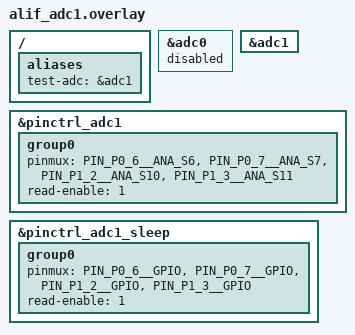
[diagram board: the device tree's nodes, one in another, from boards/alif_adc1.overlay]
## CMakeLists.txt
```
cmake_minimum_required(VERSION 3.20.0)
find_package(Zephyr REQUIRED HINTS $ENV{ZEPHYR_BASE})
project(adc)

target_sources(app PRIVATE
  src/test_adc.c
  src/temperature.c
)

if(CONFIG_TEST_ADC24)
  target_sources(app PRIVATE src/test_adc24.c)
else()
  target_sources(app PRIVATE src/test_adc12.c)
endif()

if(CONFIG_TEST_ADC_DAC)
  target_sources(app PRIVATE src/test_adc_dac.c)
endif()

if(CONFIG_TEST_ADC_THRESHOLD)
  target_sources(app PRIVATE src/test_adc_threshold.c)
endif()

if(CONFIG_TEST_ADC_PGA)
  target_sources(app PRIVATE src/test_adc_pga.c)
endif()
```

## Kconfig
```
config TEST_ADC_DIFFERENTIAL
	bool "To Test ADC in differential mode"

config TEST_ADC_CONTINUOUS
	bool "To Test ADC in continuous mode"

config TEST_ADC_MULTICH
	bool "To Test ADC in multi Channel mode"
	select TEST_ADC_CONTINUOUS
	depends on !TEST_ADC_DIFFERENTIAL || TEST_ADC24
	help
	  Alif ADC does not support multi-channel scan in single-shot mode.
	  Enabling this option also enables continuous conversion. Include
	  the continuous overlay together with the multich overlay, or use
	  a multich overlay that sets CONTINUOUS_CONVERSION.
	  Differential multi-channel is valid with ADC24 only. ADC12 has no
	  test for that combination, so it cannot be selected.

config TEST_ADC24
	bool "To Enable ADC24 testcases"

config TEST_ADC_DAC
	bool "ADC reads DAC0 loopback test"
	depends on !TEST_ADC_MULTICH && (TEST_ADC24 || !TEST_ADC_DIFFERENTIAL)
	select DAC
	help
	  Enable with -DCONFIG_TEST_ADC_DAC=y. Requires an ADC+DAC overlay
	  (alif_adc1_dac0.overlay preferred on B1, or alif_adc12_dac0 /
	  alif_adc24_dac0) so DT alias dac is present. Wire DAC0 P2_3 to
	  the ADC pin described in test_adc_dac.c / README.

config TEST_ADC_THRESHOLD
	bool "ADC comparator threshold and window test"
	help
	  Enable with -DCONFIG_TEST_ADC_THRESHOLD=y. Append a
	  thresh_above, thresh_below, or thresh_window overlay to the
	  matching base ADC overlay.

config TEST_ADC_PGA
	bool "ADC PGA gain test"
	help
	  Enable with -DCONFIG_TEST_ADC_PGA=y. Append a gain overlay
	  (alif_adc1_gain0.overlay, gain12, gain24, gain36, or gain42).
	  Do not combine with CONFIG_TEST_ADC_DAC or CONFIG_TEST_ADC_THRESHOLD.
	  Optionally pass -DCONFIG_TEST_ADC_CHn=y to pick the channel
	  (default channel 1).

config TEST_ADC_CH0
	bool "To enable ADC channel 0 testcase"
	help
	  Enable with -DCONFIG_TEST_ADC_CH0=y on the west build command.

config TEST_ADC_CH1
	bool "To enable ADC channel 1 testcase"
	help
	  Enable with -DCONFIG_TEST_ADC_CH1=y on the west build command.

config TEST_ADC_CH2
	bool "To enable ADC channel 2 testcase"
	help
	  Enable with -DCONFIG_TEST_ADC_CH2=y on the west build command.

config TEST_ADC_CH3
	bool "To enable ADC channel 3 testcase"
	help
	  Enable with -DCONFIG_TEST_ADC_CH3=y on the west build command.

config TEST_ADC_CH4
	bool "To enable ADC channel 4 testcase"
	help
	  Enable with -DCONFIG_TEST_ADC_CH4=y on the west build command.

config TEST_ADC_CH5
	bool "To enable ADC channel 5 testcase"
	help
	  Enable with -DCONFIG_TEST_ADC_CH5=y on the west build command.

config TEST_ADC_CH6
	bool "To enable ADC channel 6 (temperature) testcase"
	help
	  Enable with -DCONFIG_TEST_ADC_CH6=y on the west build command.

config TEST_ADC_CH7
	bool "To enable ADC channel 7 testcase"
	help
	  Enable with -DCONFIG_TEST_ADC_CH7=y on the west build command.

source "Kconfig.zephyr"
```

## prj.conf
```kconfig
CONFIG_ZTEST=y
CONFIG_ADC=y
CONFIG_LOG=y
CONFIG_CBPRINTF_FP_SUPPORT=y
CONFIG_USE_ALIF_HAL_ANALOG=y
CONFIG_ADC_LOG_LEVEL_INF=n
```

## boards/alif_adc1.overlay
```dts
/ {
	aliases {
		test-adc = &adc1;
	};
};

&adc0 {
	status = "disabled";
};

&adc1 {
	status = "okay";
};

/*
 * ADC1 channels 2 and 3 are P1_0 and P1_1, which are also UART2 RX/TX
 * (the RTSS-HE console). Leave those pins as UART so the boot banner
 * and ztest log stay visible. Channels 0, 1, 4, and 5 are unchanged.
 */
&pinctrl_adc1 {
	group0 {
		pinmux = <PIN_P0_6__ANA_S6>,
			 <PIN_P0_7__ANA_S7>,
			 <PIN_P1_2__ANA_S10>,
			 <PIN_P1_3__ANA_S11>;
		read-enable = <1>;
	};
};

&pinctrl_adc1_sleep {
	group0 {
		pinmux = <PIN_P0_6__GPIO>,
			 <PIN_P0_7__GPIO>,
			 <PIN_P1_2__GPIO>,
			 <PIN_P1_3__GPIO>;
		read-enable = <1>;
	};
};
```

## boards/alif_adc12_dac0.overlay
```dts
/ {
	aliases {
		test-adc = &adc0;
		dac = &dac0;
	};
};

&adc0 {
	status = "okay";
};

&dac0 {
	status = "okay";
};
```

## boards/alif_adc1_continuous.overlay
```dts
&adc0 {
	status = "disabled";
};

&adc1 {
	adc_conversion_mode	= "CONTINUOUS_CONVERSION";
	status = "okay";
};
```

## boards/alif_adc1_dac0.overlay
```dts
/*
 * ADC12 instance 1 + DAC0 loopback (Balletto / B1 preferred).
 * Wire DAC0 P2_3 to ADC1 channel 0 P0_6.
 * Avoids ADC0 channel 0 P0_0, which shares UART0 RX and often sits near 1.8 V.
 */
/ {
	aliases {
		test-adc = &adc1;
		dac = &dac0;
	};
};

&adc0 {
	status = "disabled";
};

&adc1 {
	status = "okay";
};

&dac0 {
	status = "okay";
};
```

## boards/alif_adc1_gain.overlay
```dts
&adc1 {
		pga_enable;
		pga_gain = "ADC_PGA_GAIN_42_DB";
};
```

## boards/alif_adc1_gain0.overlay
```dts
&adc1 {
		pga_enable;
		pga_gain = "ADC_PGA_GAIN_0_DB";
};
```

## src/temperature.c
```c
/* Copyright (C) Alif Semiconductor - All Rights Reserved.
 * Use, distribution and modification of this code is permitted under the
 * terms stated in the Alif Semiconductor Software License Agreement
 *
 * You should have received a copy of the Alif Semiconductor Software
 * License Agreement with this file. If not, please write to:
 * contact@alifsemi.com, or visit: https://alifsemi.com/license
 */

#include "temperature.h"

const float tempData[][2] = {
	{918, -40.0},
	{919, -39.6},
	{920, -39.2},
	{921, -38.8},
	{922, -38.4},
	{923, -38.0},
	{924, -37.6},
	{925, -37.2},
	{926, -36.8},
	{927, -36.4},
	{928, -36.0},
	{929, -35.6},
	{930, -35.2},
	{931, -34.8},
	{932, -34.4},
	{933, -34.0},
	{934, -33.6},
	{935, -33.2},
	{936, -32.8},
	{937, -32.4},
	{938, -32.0},
	{939, -31.6},
	{940, -31.2},
	{941, -30.8},
	{942, -30.4},
	{943, -30.0},
	{944, -29.8},
	{945, -29.7},
	{946, -29.5},
	{947, -29.3},
	{948, -29.2},
	{949, -29.0},
	{950, -28.8},
	{951, -28.7},
	{952, -28.5},
	{953, -28.3},
	{954, -28.2},
	{955, -28.0},
	{956, -27.8},
	{957, -27.7},
	{958, -27.5},
	{959, -27.3},
	{960, -27.2},
	{961, -27.0},
	{962, -26.8},
	{963, -26.7},
	{964, -26.5},
	{965, -26.3},
	{966, -26.2},
	{967, -26.0},
	{968, -25.8},
	{969, -25.7},
	{970, -25.5},
	{971, -25.3},
	{972, -25.2},
	{973, -25.0},
	{974, -24.8},
	{975, -24.7},
	{976, -24.5},
	{977, -24.3},
	{978, -24.2},
	{979, -24.0},
	{980, -23.8},
	{981, -23.7},
	{982, -23.5},
	{983, -23.3},
	{984, -23.2},
	{985, -23.0},
	{986, -22.8},
	{987, -22.7},
	{988, -22.5},
	{989, -22.3},
	{990, -22.2},
	{991, -22.0},
	{992, -21.8},
	{993, -21.7},
	{994, -21.5},
	{995, -21.3},
	{996, -21.2},
	{997, -21.0},
	{998, -20.8},
	{999, -20.7},
	{1000, -20.5},
	{1001, -20.3},
	{1002, -20.2},
	{1003, -20.0},
	{1004, -19.2},
	{1005, -18.5},
	{1006, -17.7},
	{1007, -16.9},
	{1008, -16.2},
	{1009, -15.4},
	{1010, -14.6},
	{1011, -13.8},
	{1012, -13.1},
	{1013, -12.3},
	{1014, -11.5},
	{1015, -10.8},
	{1016, -10.0},
	{1017, -9.4},
	{1018, -8.8},
	{1019, -8.1},
	{1020, -7.5},
	{1021, -6.9},
	{1022, -6.3},
	{1023, -5.6},
	{1024, -5.0},
	{1025, -4.4},
	{1026, -3.8},
	{1027, -3.1},
	{1028, -2.5},
	{1029, -1.9},
	{1030, -1.3},
	{1031, -0.6},
	{1032, 0.0},
	{1033, 0.7},
	{1034, 1.3},
	{1035, 2.0},
	{1036, 2.7},
	{1037, 3.3},
	{1038, 4.0},
	{1039, 4.7},
	{1040, 5.3},
	{1041, 6.0},
	{1042, 6.7},
	{1043, 7.3},
	{1044, 8.0},
	{1045, 8.7},
	{1046, 9.3},
	{1047, 10.0},
	{1048, 10.4},
	{1049, 10.9},
	{1050, 11.3},
	{1051, 11.7},
	{1052, 12.2},
	{1053, 12.6},
	{1054, 13.0},
	{1055, 13.5},
	{1056, 13.9},
	{1057, 14.3},
	{1058, 14.8},
	{1059, 15.2},
	{1060, 15.7},
	{1061, 16.1},
	{1062, 16.5},
	{1063, 17.0},
	{1064, 17.4},
	{1065, 17.8},
	{1066, 18.3},
	{1067, 18.7},
	{1068, 19.1},
	{1069, 19.6},
	{1070, 20.0},
	{1071, 20.2},
	{1072, 20.3},
	{1073, 20.5},
	{1074, 20.7},
	{1075, 20.9},
	{1076, 21.0},
	{1077, 21.2},
	{1078, 21.4},
	{1079, 21.6},
	{1080, 21.7},
	{1081, 21.9},
	{1082, 22.1},
	{1083, 22.2},
	{1084, 22.4},
	{1085, 22.6},
	{1086, 22.8},
	{1087, 22.9},
	{1088, 23.1},
	{1089, 23.3},
	{1090, 23.4},
	{1091, 23.6},
	{1092, 23.8},
	{1093, 24.0},
	{1094, 24.1},
	{1095, 24.3},
	{1096, 24.5},
	{1097, 24.7},
	{1098, 24.8},
	{1099, 25.0},
	{1100, 25.2},
	{1101, 25.3},
	{1102, 25.5},
	{1103, 25.7},
	{1104, 25.9},
	{1105, 26.0},
	{1106, 26.2},
	{1107, 26.4},
	{1108, 26.6},
	{1109, 26.7},
	{1110, 26.9},
	{1111, 27.1},
	{1112, 27.2},
	{1113, 27.4},
	{1114, 27.6},
	{1115, 27.8},
	{1116, 27.9},
	{1117, 28.1},
	{1118, 28.3},
	{1119, 28.4},
	{1120, 28.6},
	{1121, 28.8},
	{1122, 29.0},
	{1123, 29.1},
	{1124, 29.3},
	{1125, 29.5},
	{1126, 29.7},
	{1127, 29.8},
	{1128, 30.0},
	{1129, 30.3},
	{1130, 30.5},
	{1131, 30.8},
	{1132, 31.0},
	{1133, 31.3},
	{1134, 31.5},
	{1135, 31.8},
	{1136, 32.0},
	{1137, 32.3},
	{1138, 32.5},
	{1139, 32.8},
	{1140, 33.0},
	{1141, 33.3},
	{1142, 33.5},
	{1143, 33.8},
	{1144, 34.0},
	{1145, 34.3},
	{1146, 34.5},
	{1147, 34.8},
	{1148, 35.0},
	{1149, 35.3},
	{1150, 35.5},
	{1151, 35.8},
	{1152, 36.0},
	{1153, 36.3},
	{1154, 36.5},
	{1155, 36.8},
	{1156, 37.0},
	{1157, 37.3},
	{1158, 37.5},
	{1159, 37.8},
	{1160, 38.0},
	{1161, 38.3},
	{1162, 38.5},
	{1163, 38.8},
	{1164, 39.0},
	{1165, 39.3},
	{1166, 39.5},
	{1167, 39.8},
	{1168, 40.0},
	{1169, 40.5},
	{1170, 40.9},
	{1171, 41.4},
	{1172, 41.8},
	{1173, 42.3},
	{1174, 42.7},
	{1175, 43.2},
	{1176, 43.6},
	{1177, 44.1},
	{1178, 44.5},
	{1179, 45.0},
	{1180, 45.5},
	{1181, 45.9},
	{1182, 46.4},
	{1183, 46.8},
	{1184, 47.3},
	{1185, 47.7},
	{1186, 48.2},
	{1187, 48.6},
	{1188, 49.1},
	{1189, 49.5},
	{1190, 50.0},
	{1191, 50.2},
	{1192, 50.3},
	{1193, 50.5},
	{1194, 50.7},
	{1195, 50.9},
	{1196, 51.0},
	{1197, 51.2},
	{1198, 51.4},
	{1199, 51.6},
	{1200, 51.7},
	{1201, 51.9},
	{1202, 52.1},
	{1203, 52.2},
	{1204, 52.4},
	{1205, 52.6},
	{1206, 52.8},
	{1207, 52.9},
	{1208, 53.1},
	{1209, 53.3},
	{1210, 53.4},
	{1211, 53.6},
	{1212, 53.8},
	{1213, 54.0},
	{1214, 54.1},
	{1215, 54.3},
	{1216, 54.5},
	{1217, 54.7},
	{1218, 54.8},
	{1219, 55.0},
	{1220, 55.2},
	{1221, 55.3},
	{1222, 55.5},
	{1223, 55.7},
	{1224, 55.9},
	{1225, 56.0},
	{1226, 56.2},
	{1227, 56.4},
	{1228, 56.6},
	{1229, 56.7},
	{1230, 56.9},
	{1231, 57.1},
	{1232, 57.2},
	{1233, 57.4},
	{1234, 57.6},
	{1235, 57.8},
	{1236, 57.9},
	{1237, 58.1},
	{1238, 58.3},
	{1239, 58.4},
	{1240, 58.6},
	{1241, 58.8},
	{1242, 59.0},
	{1243, 59.1},
	{1244, 59.3},
	{1245, 59.5},
	{1246, 59.7},
	{1247, 59.8},
	{1248, 60.0},
	{1249, 60.3},
	{1250, 60.7},
	{1251, 61.0},
	{1252, 61.3},
	{1253, 61.7},
	{1254, 62.0},
	{1255, 62.3},
	{1256, 62.7},
	{1257, 63.0},
	{1258, 63.3},
	{1259, 63.7},
	{1260, 64.0},
	{1261, 64.3},
	{1262, 64.7},
	{1263, 65.0},
	{1264, 65.3},
	{1265, 65.7},
	{1266, 66.0},
	{1267, 66.3},
	{1268, 66.7},
	{1269, 67.0},
	{1270, 67.3},
	{1271, 67.7},
	{1272, 68.0},
	{1273, 68.3},
	{1274, 68.7},
	{1275, 69.0},
	{1276, 69.3},
	{1277, 69.7},
	{1278, 70.0},
	{1279, 70.4},
	{1280, 70.9},
	{1281, 71.3},
	{1282, 71.7},
	{1283, 72.2},
	{1284, 72.6},
	{1285, 73.0},
	{1286, 73.5},
	{1287, 73.9},
	{1288, 74.3},
	{1289, 74.8},
	{1290, 75.2},
	{1291, 75.7},
	{1292, 76.1},
	{1293, 76.5},
	{1294, 77.0},
	{1295, 77.4},
	{1296, 77.8},
	{1297, 78.3},
	{1298, 78.7},
	{1299, 79.1},
	{1300, 79.6},
	{1301, 80.0},
	{1302, 80.5},
	{1303, 81.1},
	{1304, 81.6},
	{1305, 82.1},
	{1306, 82.6},
	{1307, 83.2},
	{1308, 83.7},
	{1309, 84.2},
	{1310, 84.7},
	{1311, 85.3},
	{1312, 85.8},
	{1313, 86.3},
	{1314, 86.8},
	{1315, 87.4},
	{1316, 87.9},
	{1317, 88.4},
	{1318, 88.9},
	{1319, 89.5},
	{1320, 90.0}
};

float get_temperature(uint32_t adc_value)
{
	uint32_t i;

	/* check for temperature operating range */
	if (adc_value < tempData[0][0] || (adc_value > tempData[MAX_TEMP_RANGE][0])) {
		return -1;
	}

	for (i = 0; i < ARRAY_SIZE(tempData) ; i++) {
		/* check if value matches with tempdata */
		if (adc_value == tempData[i][0]) {
			return tempData[i][1];
		}
	}

	/* no entry for this value */
	return -1;
}
```

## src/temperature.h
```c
/* Copyright (C) Alif Semiconductor - All Rights Reserved.
 * Use, distribution and modification of this code is permitted under the
 * terms stated in the Alif Semiconductor Software License Agreement
 *
 * You should have received a copy of the Alif Semiconductor Software
 * License Agreement with this file. If not, please write to:
 * contact@alifsemi.com, or visit: https://alifsemi.com/license
 */

#ifndef TEMPERATURE_H_
#define TEMPERATURE_H_

#include <stdint.h>

#include <zephyr/sys/util.h>

#define MAX_TEMP_RANGE 402

/* Declaration of the 2D array and function */
extern const float tempData[][2];
float get_temperature(uint32_t adc_value);

#endif /* TEMPERATURE_H_ */
```

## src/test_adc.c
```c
/* Copyright (C) Alif Semiconductor - All Rights Reserved.
 * Use, distribution and modification of this code is permitted under the
 * terms stated in the Alif Semiconductor Software License Agreement
 *
 * You should have received a copy of the Alif Semiconductor Software
 * License Agreement with this file. If not, please write to:
 * contact@alifsemi.com, or visit: https://alifsemi.com/license
 */

#include <string.h>

#include "test_adc.h"

LOG_MODULE_REGISTER(ALIF_ADC, LOG_LEVEL_INF);

uint32_t buffer[8];
uint32_t All_channel;
uint32_t m_samplings_done;
uint8_t comparator;
uint32_t comp_value[MAX_NUM_THRESHOLD];

enum adc_action adc_call_back(const struct device *dev,
			      const struct adc_sequence *sequence,
			      uint16_t sampling_index)
{
	ARG_UNUSED(dev);
	ARG_UNUSED(sequence);

	LOG_INF("sampling index 0x%X", sampling_index);

	if (comparator & ADC_COMPARATOR_THRESHOLD_ABOVE_A) {
		comp_value[0] += 1;
	}
	if (comparator & ADC_COMPARATOR_THRESHOLD_ABOVE_B) {
		comp_value[1] += 1;
	}
	if (comparator & ADC_COMPARATOR_THRESHOLD_BELOW_A) {
		comp_value[2] += 1;
	}
	if (comparator & ADC_COMPARATOR_THRESHOLD_BELOW_B) {
		comp_value[3] += 1;
	}
	if (comparator & ADC_COMPARATOR_THRESHOLD_BETWEEN_A_B) {
		comp_value[4] += 1;
	}
	if (comparator & ADC_COMPARATOR_THRESHOLD_OUTSIDE_A_B) {
		comp_value[5] += 1;
	}

	++m_samplings_done;

	if (m_samplings_done < 2) {
		return ADC_ACTION_REPEAT;
	}

	return ADC_ACTION_FINISH;
}

void adc_test_reset(void)
{
	uint32_t i;

	m_samplings_done = 0;
	comparator = 0;
	memset(comp_value, 0, sizeof(comp_value));
	for (i = 0; i < ARRAY_SIZE(buffer); i++) {
		buffer[i] = ADC_SAMPLE_SENTINEL;
	}
}

void adc_assert_samples(uint32_t channels)
{
	uint32_t count = POPCOUNT(channels);
	uint32_t i;

	zassert_equal(m_samplings_done, 2,
		      "sampling callback count %u, expected 2",
		      m_samplings_done);
	zassert_true(count > 0 && count <= ARRAY_SIZE(buffer),
		     "channel mask 0x%x does not fit the sample buffer",
		     channels);

	for (i = 0; i < count; i++) {
		zassert_not_equal(buffer[i], ADC_SAMPLE_SENTINEL,
				  "requested channel sample %u was not written", i);
	}
}

static void adc_before(void *fixture)
{
	ARG_UNUSED(fixture);
	adc_test_reset();
}

#if CONFIG_TEST_ADC_MULTICH
#if !DT_NODE_HAS_PROP(DT_ALIAS(test_adc), adc_channel_scan)
#error "MULTICH needs adc_channel_scan (use alif_adc1/24_multich.overlay)"
#elif !DT_ENUM_HAS_VALUE(DT_ALIAS(test_adc), adc_channel_scan, MULTIPLE_CHANNEL_SCAN)
#error "adc_channel_scan must be MULTIPLE_CHANNEL_SCAN"
#endif
#if !DT_NODE_HAS_PROP(DT_ALIAS(test_adc), adc_conversion_mode)
#error "MULTICH needs CONTINUOUS_CONVERSION (single-shot + scan unsupported)"
#elif !DT_ENUM_HAS_VALUE(DT_ALIAS(test_adc), adc_conversion_mode, CONTINUOUS_CONVERSION)
#error "MULTICH needs CONTINUOUS_CONVERSION (single-shot + scan unsupported)"
#endif
#endif

#if CONFIG_TEST_ADC_CONTINUOUS
#if !DT_NODE_HAS_PROP(DT_ALIAS(test_adc), adc_conversion_mode)
#error "CONTINUOUS needs adc_conversion_mode (use continuous overlay)"
#elif !DT_ENUM_HAS_VALUE(DT_ALIAS(test_adc), adc_conversion_mode, CONTINUOUS_CONVERSION)
#error "adc_conversion_mode must be CONTINUOUS_CONVERSION"
#endif
#endif

#if CONFIG_TEST_ADC_THRESHOLD
#include <zephyr/dt-bindings/adc/adc_alif.h>
#if !DT_NODE_HAS_PROP(DT_ALIAS(test_adc), interrupt_en)
#error "THRESHOLD needs interrupt_en (append a thresh_above/below/window overlay)"
#elif ((DT_PROP(DT_ALIAS(test_adc), interrupt_en) & \
	(ADC_COMPA_INTERRUPT | ADC_COMPB_INTERRUPT)) != \
	(ADC_COMPA_INTERRUPT | ADC_COMPB_INTERRUPT))
#error "THRESHOLD needs COMPA+COMPB; append a thresh_* overlay"
#endif
#endif

#if CONFIG_TEST_ADC_PGA
#if !DT_PROP_OR(DT_ALIAS(test_adc), pga_enable, 0)
#error "PGA needs pga_enable; append a gain overlay (e.g. alif_adc1_gain0.overlay)"
#endif
#endif

#if (CONFIG_TEST_ADC24)
#if (CONFIG_TEST_ADC_MULTICH)
ZTEST_SUITE(adc24_multi_channel, NULL, NULL, adc_before, NULL, NULL);
#else
ZTEST_SUITE(adc24_differential, NULL, NULL, adc_before, NULL, NULL);
#endif
#else
#if (CONFIG_TEST_ADC_MULTICH)
ZTEST_SUITE(adc12_multi_channel, NULL, NULL, adc_before, NULL, NULL);
#elif (CONFIG_TEST_ADC_DIFFERENTIAL)
ZTEST_SUITE(adc12_differential, NULL, NULL, adc_before, NULL, NULL);
#else
ZTEST_SUITE(adc_single_ended, NULL, NULL, adc_before, NULL, NULL);
#endif
#endif
```

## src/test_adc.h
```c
/* Copyright (C) Alif Semiconductor - All Rights Reserved.
 * Use, distribution and modification of this code is permitted under the
 * terms stated in the Alif Semiconductor Software License Agreement
 *
 * You should have received a copy of the Alif Semiconductor Software
 * License Agreement with this file. If not, please write to:
 * contact@alifsemi.com, or visit: https://alifsemi.com/license
 */
#ifndef TEST_ADC_H_
#define TEST_ADC_H_

#include <inttypes.h>
#include <stddef.h>
#include <stdint.h>

#include <zephyr/device.h>
#include <zephyr/devicetree.h>
#include <zephyr/drivers/adc.h>
#include <zephyr/kernel.h>
#include <zephyr/sys/printk.h>
#include <zephyr/sys/util.h>
#include "temperature.h"
#include <zephyr/ztest.h>
#include <zephyr/logging/log.h>


extern uint32_t buffer[8];
extern uint32_t All_channel;
#define ADC_CHANNEL_0				(0x00)
#define ADC_CHANNEL_1				(0x01)
#define ADC_CHANNEL_2				(0x02)
#define ADC_CHANNEL_3				(0x03)
#define ADC_CHANNEL_4				(0x04)
#define ADC_CHANNEL_5				(0x05)
#define ADC_CHANNEL_6				(0x06)
#define ADC_CHANNEL_7				(0x07)
#define ADC_CHANNEL_8				(0x08)

/****ADC MASK CHANNEL****/
#define ADC_UNMASK_CHANNEL_0			(1 << 0)
#define ADC_UNMASK_CHANNEL_1			(1 << 1)
#define ADC_UNMASK_CHANNEL_2			(1 << 2)
#define ADC_UNMASK_CHANNEL_3			(1 << 3)
#define ADC_UNMASK_CHANNEL_4			(1 << 4)
#define ADC_UNMASK_CHANNEL_5			(1 << 5)
#define ADC_UNMASK_CHANNEL_6			(1 << 6)
#define ADC_UNMASK_CHANNEL_7			(1 << 7)
#define ADC_UNMASK_CHANNEL_8			(1 << 8)

#define ADC_COMPARATOR_THRESHOLD_ABOVE_A	(1 << 0)
#define ADC_COMPARATOR_THRESHOLD_ABOVE_B	(1 << 1)
#define ADC_COMPARATOR_THRESHOLD_BELOW_A	(1 << 2)
#define ADC_COMPARATOR_THRESHOLD_BELOW_B	(1 << 3)
#define ADC_COMPARATOR_THRESHOLD_BETWEEN_A_B	(1 << 4)
#define ADC_COMPARATOR_THRESHOLD_OUTSIDE_A_B	(1 << 5)

#define TEMPERATURE_SENSOR			ADC_CHANNEL_6
#define MAX_NUM_THRESHOLD			(6)

extern uint32_t m_samplings_done;
extern uint8_t comparator;

extern uint32_t comp_value[MAX_NUM_THRESHOLD];

/*
 * Not a legal conversion result. Single-ended samples stay within 20 bits.
 * Differential samples are sign-extended, so a negative value has the sign
 * bit and every bit above it set. This value has bit 30 set and bit 31 clear.
 */
#define ADC_SAMPLE_SENTINEL			0x7FFFFFFF

#define ADC	DT_ALIAS(test_adc)

enum adc_action adc_call_back(const struct device *dev,
			      const struct adc_sequence *sequence,
			      uint16_t sampling_index);

void adc_test_reset(void);

void adc_assert_samples(uint32_t channels);

#endif /* TEST_ADC_H_ */
```

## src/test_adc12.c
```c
/* Copyright (C) Alif Semiconductor - All Rights Reserved.
 * Use, distribution and modification of this code is permitted under the
 * terms stated in the Alif Semiconductor Software License Agreement
 *
 * You should have received a copy of the Alif Semiconductor Software
 * License Agreement with this file. If not, please write to:
 * contact@alifsemi.com, or visit: https://alifsemi.com/license
 */

#include "test_adc.h"

#if !CONFIG_TEST_ADC24

LOG_MODULE_DECLARE(ALIF_ADC, LOG_LEVEL_INF);

static int test_channels(int channel, int mask)
{
	float temp;
	int ret;
	uint32_t channels;

	struct adc_sequence_options adc_seq_options = {
		.callback	= adc_call_back,
		.user_data	= (uint8_t *)&comparator,
	};

	const struct device *adc_dev = DEVICE_DT_GET(ADC);

	zassert_true(device_is_ready(adc_dev), "ADC device is not ready");

	struct adc_channel_cfg channel_cfg = {
#if CONFIG_TEST_ADC_DIFFERENTIAL
		.differential = 1,
#else
		.differential = 0,
#endif
		.channel_id   = All_channel ? ADC_CHANNEL_0 : channel,
	};

	if (IS_ENABLED(CONFIG_TEST_ADC_MULTICH)) {
		LOG_INF("ADC12 multi-channel scan (continuous)");
	} else if (All_channel && IS_ENABLED(CONFIG_TEST_ADC_DIFFERENTIAL)) {
		LOG_INF("ADC12 with differential");
	} else if (!IS_ENABLED(CONFIG_TEST_ADC_DIFFERENTIAL) &&
		   IS_ENABLED(CONFIG_TEST_ADC_CONTINUOUS)) {
		LOG_INF("ADC12 single ended continuous");
	} else if (IS_ENABLED(CONFIG_TEST_ADC_DIFFERENTIAL) &&
		   IS_ENABLED(CONFIG_TEST_ADC_CONTINUOUS)) {
		LOG_INF("ADC12 Differential and continuous feature selected");
	} else {
		LOG_INF("ADC12 Single ended");
	}

	if (IS_ENABLED(CONFIG_TEST_ADC_CONTINUOUS) || All_channel) {
#if CONFIG_TEST_ADC_DIFFERENTIAL
		channels = ADC_UNMASK_CHANNEL_0 | ADC_UNMASK_CHANNEL_1 | ADC_UNMASK_CHANNEL_2;
#else
		/* Balletto ADC12 has no channel 7 (Vref). E1C, E7, and E8 keep it. */
		channels = ADC_UNMASK_CHANNEL_0 | ADC_UNMASK_CHANNEL_1 | ADC_UNMASK_CHANNEL_2
			 | ADC_UNMASK_CHANNEL_3 | ADC_UNMASK_CHANNEL_4 | ADC_UNMASK_CHANNEL_5
			 | ADC_UNMASK_CHANNEL_6;
		if (!IS_ENABLED(CONFIG_SOC_FAMILY_BALLETTO)) {
			channels |= ADC_UNMASK_CHANNEL_7;
		}
#endif
	} else {
		channels = mask;
	}

	struct adc_sequence sequence = {
		.options	= &adc_seq_options,
		.buffer		= (void *)buffer,
		.buffer_size	= sizeof(buffer),
		.channels	= channels,
	};

	/* Set the channel */
	ret = adc_channel_setup(adc_dev, &channel_cfg);
	if (!IS_ENABLED(CONFIG_TEST_ADC_CONTINUOUS) &&
	    IS_ENABLED(CONFIG_TEST_ADC_DIFFERENTIAL) &&
	    (channel > ADC_CHANNEL_2)) {
		zassert_equal(ret, -EINVAL,
			      "invalid channel setup passed, ret %d", ret);
		LOG_INF("channel setup failed as expected, ret %d", ret);
		return TC_PASS;
	}
	zassert_equal(ret, 0, "Unable set up channel, code %d", ret);

	/* Start reading the samples */
	ret = adc_read(adc_dev, &sequence);
	zassert_equal(ret, 0, "adc_read() failed with code %d", ret);
	adc_assert_samples(channels);

	LOG_INF("Allocated memory buffer Address is %p", (void *)buffer);

	if (channel_cfg.channel_id == ADC_CHANNEL_6) {
		LOG_INF("Allocated memory buffer Address is %p and value is %x",
			(void *)buffer, buffer[0]);
		temp = (float) get_temperature(buffer[0]);
		if (temp == -1) {
			LOG_ERR(" Error: Temperature is outside range");
			ztest_test_fail();
		} else {
			LOG_INF("Current temp %0.1f C", (double)temp);
		}
	}

#if CONFIG_TEST_ADC_CONTINUOUS
	for (uint32_t i = 0; i < POPCOUNT(channels); i++) {
		LOG_INF("Channel%d value is %x", i, buffer[i]);
	}
#else
	LOG_INF("Channel %d value is %x", channel, buffer[0]);
#endif

	LOG_INF("ADC sampling Done");
	return TC_PASS;
}

#if !(CONFIG_TEST_ADC_DIFFERENTIAL || CONFIG_TEST_ADC_CONTINUOUS || \
	CONFIG_TEST_ADC_MULTICH || CONFIG_TEST_ADC_PGA || CONFIG_TEST_ADC_THRESHOLD)

#if CONFIG_TEST_ADC_CH0
ZTEST(adc_single_ended, test_adc_single_ended_input_channel0)
{
	zassert_true(test_channels(ADC_CHANNEL_0, ADC_UNMASK_CHANNEL_0) == TC_PASS);
}
#endif

#if CONFIG_TEST_ADC_CH1
ZTEST(adc_single_ended, test_adc_single_ended_input_channel1)
{
	zassert_true(test_channels(ADC_CHANNEL_1, ADC_UNMASK_CHANNEL_1) == TC_PASS);
}
#endif

#if CONFIG_TEST_ADC_CH2
ZTEST(adc_single_ended, test_adc_single_ended_input_channel2)
{
	zassert_true(test_channels(ADC_CHANNEL_2, ADC_UNMASK_CHANNEL_2) == TC_PASS);
}
#endif

#if CONFIG_TEST_ADC_CH3
ZTEST(adc_single_ended, test_adc_single_ended_input_channel3)
{
	zassert_true(test_channels(ADC_CHANNEL_3, ADC_UNMASK_CHANNEL_3) == TC_PASS);
}
#endif

#if CONFIG_TEST_ADC_CH4
ZTEST(adc_single_ended, test_adc_single_ended_input_channel4)
{
	zassert_true(test_channels(ADC_CHANNEL_4, ADC_UNMASK_CHANNEL_4) == TC_PASS);
}
#endif

#if CONFIG_TEST_ADC_CH5
ZTEST(adc_single_ended, test_adc_single_ended_input_channel5)
{
	zassert_true(test_channels(ADC_CHANNEL_5, ADC_UNMASK_CHANNEL_5) == TC_PASS);
}
#endif

#if CONFIG_TEST_ADC_CH6
ZTEST(adc_single_ended, test_adc_single_ended_input_channel6)
{
	zassert_true(test_channels(ADC_CHANNEL_6, ADC_UNMASK_CHANNEL_6) == TC_PASS);
}
#endif

#if CONFIG_TEST_ADC_CH7 && !IS_ENABLED(CONFIG_SOC_FAMILY_BALLETTO)
ZTEST(adc_single_ended, test_adc_single_ended_input_channel7)
{
	zassert_true(test_channels(ADC_CHANNEL_7, ADC_UNMASK_CHANNEL_7) == TC_PASS);
}
#endif
#endif

#if (CONFIG_TEST_ADC_CONTINUOUS && !CONFIG_TEST_ADC_DIFFERENTIAL && !CONFIG_TEST_ADC_MULTICH)
ZTEST(adc_single_ended, test_adc_ContinuousMode)
{
	All_channel = 1;
	zassert_true(test_channels(0, 0) == TC_PASS);
	All_channel = 0;
}
#endif

#if (CONFIG_TEST_ADC_MULTICH && !CONFIG_TEST_ADC_DIFFERENTIAL)
ZTEST(adc12_multi_channel, test_adc_continuous_Mode_with_multi_channel)
{
	All_channel = 1;
	zassert_true(test_channels(0, 0) == TC_PASS);
	All_channel = 0;
}
#endif

#if (CONFIG_TEST_ADC_DIFFERENTIAL && !CONFIG_TEST_ADC_CONTINUOUS && !CONFIG_TEST_ADC_MULTICH)

#if (CONFIG_TEST_ADC_CH0 && CONFIG_TEST_ADC_CH1)
ZTEST(adc12_differential, test_adc_channel_0_diff_input)
{
	zassert_true(test_channels(ADC_CHANNEL_0, ADC_UNMASK_CHANNEL_0) == TC_PASS);
}
#endif

#if (CONFIG_TEST_ADC_CH2 && CONFIG_TEST_ADC_CH3)
ZTEST(adc12_differential, test_adc_channel_1_diff_input)
{
	zassert_true(test_channels(ADC_CHANNEL_1, ADC_UNMASK_CHANNEL_1) == TC_PASS);
}
#endif

#if (CONFIG_TEST_ADC_CH4 && CONFIG_TEST_ADC_CH5)
ZTEST(adc12_differential, test_adc_channel_2_diff_input)
{
	zassert_true(test_channels(ADC_CHANNEL_2, ADC_UNMASK_CHANNEL_2) == TC_PASS);
}
#endif
#if !(CONFIG_TEST_ADC_CH0 || CONFIG_TEST_ADC_CH1 || \
	CONFIG_TEST_ADC_CH2 || CONFIG_TEST_ADC_CH3 || \
	CONFIG_TEST_ADC_CH4 || CONFIG_TEST_ADC_CH5 || \
	CONFIG_TEST_ADC_CH6 || CONFIG_TEST_ADC_CH7)
ZTEST(adc12_differential, test_adc12_channel_3_diff_input_error_scenario)
{
	zassert_true(test_channels(ADC_CHANNEL_3, ADC_UNMASK_CHANNEL_3) == TC_PASS);
}

ZTEST(adc12_differential, test_adc12_channel_4_diff_input_error_scenario)
{
	zassert_true(test_channels(ADC_CHANNEL_4, ADC_UNMASK_CHANNEL_4) == TC_PASS);
}

ZTEST(adc12_differential, test_adc12_channel_5_diff_input_error_scenario)
{
	zassert_true(test_channels(ADC_CHANNEL_5, ADC_UNMASK_CHANNEL_5) == TC_PASS);
}

ZTEST(adc12_differential, test_adc12_channel_6_diff_input_error_scenario)
{
	zassert_true(test_channels(ADC_CHANNEL_6, ADC_UNMASK_CHANNEL_6) == TC_PASS);
}

ZTEST(adc12_differential, test_adc12_channel_7_diff_input_error_scenario)
{
	zassert_true(test_channels(ADC_CHANNEL_7, ADC_UNMASK_CHANNEL_7) == TC_PASS);
}
#endif
#endif
#if (CONFIG_TEST_ADC_CONTINUOUS && CONFIG_TEST_ADC_DIFFERENTIAL && !CONFIG_TEST_ADC_MULTICH)
ZTEST(adc12_differential, test_adc_continuousMode)
{
	All_channel = 1;
	zassert_true(test_channels(0, 0) == TC_PASS);
	All_channel = 0;
}
#endif

#endif /* !CONFIG_TEST_ADC24 */
```

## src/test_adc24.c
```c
/* Copyright (C) Alif Semiconductor - All Rights Reserved.
 * Use, distribution and modification of this code is permitted under the
 * terms stated in the Alif Semiconductor Software License Agreement
 *
 * You should have received a copy of the Alif Semiconductor Software
 * License Agreement with this file. If not, please write to:
 * contact@alifsemi.com, or visit: https://alifsemi.com/license
 */

#include <inttypes.h>
#include <stddef.h>
#include <stdint.h>

#include <zephyr/device.h>
#include <zephyr/devicetree.h>
#include <zephyr/drivers/adc.h>
#include <zephyr/kernel.h>
#include <zephyr/sys/printk.h>
#include <zephyr/sys/util.h>
#include "temperature.h"
#include <zephyr/ztest.h>
#include <zephyr/logging/log.h>

#include "test_adc.h"

#if CONFIG_TEST_ADC24

LOG_MODULE_DECLARE(ALIF_ADC, LOG_LEVEL_INF);

static int test_channels(int channel, int mask)
{
	int ret;
	uint32_t channels;

	struct adc_sequence_options adc_seq_options = {
		.callback	= adc_call_back,
		.user_data	= (uint8_t *)&comparator,
	};

	const struct device *adc_dev = DEVICE_DT_GET(ADC);

	zassert_true(device_is_ready(adc_dev), "ADC device is not ready");

	struct adc_channel_cfg channel_cfg = {
		.differential = 1,
		.channel_id   = All_channel ? ADC_CHANNEL_0 : channel,
	};

	if (IS_ENABLED(CONFIG_TEST_ADC_CONTINUOUS) || All_channel) {
		channels = ADC_UNMASK_CHANNEL_0 | ADC_UNMASK_CHANNEL_1
			 | ADC_UNMASK_CHANNEL_2 | ADC_UNMASK_CHANNEL_3;
	} else {
		channels = mask;
	}

	struct adc_sequence sequence = {
		.options	= &adc_seq_options,
		.buffer		= (void *)buffer,
		.buffer_size	= sizeof(buffer),
		.channels	= channels,
	};

	/* Set the channel */
	ret = adc_channel_setup(adc_dev, &channel_cfg);
	if (channel > ADC_CHANNEL_3) {
		zassert_equal(ret, -EINVAL,
			      "invalid channel setup passed, ret %d", ret);
		LOG_INF("channel setup failed as expected, ret %d", ret);
		return TC_PASS;
	}
	zassert_equal(ret, 0, "Unable set up channel, code %d", ret);

	/* Start reading the samples */
	ret = adc_read(adc_dev, &sequence);
	zassert_equal(ret, 0, "adc_read() failed with code %d", ret);
	adc_assert_samples(channels);

	LOG_INF("Allocated memory buffer Address is %p", (void *)buffer);

#if CONFIG_TEST_ADC_CONTINUOUS
	for (int i = 0; i < 4; i++) {
		LOG_INF("Channel%d value is %x", i, buffer[i]);
	}
#else
	LOG_INF("Channel %d value is %x", channel, buffer[0]);
#endif

	LOG_INF("ADC sampling Done");
	return TC_PASS;
}

#if (!CONFIG_TEST_ADC_CONTINUOUS && !CONFIG_TEST_ADC_MULTICH && \
	!CONFIG_TEST_ADC_PGA && !CONFIG_TEST_ADC_THRESHOLD)

#if CONFIG_TEST_ADC_CH0
ZTEST(adc24_differential, test_adc24_channel_0_diff_input)
{
	zassert_true(test_channels(ADC_CHANNEL_0, ADC_UNMASK_CHANNEL_0) == TC_PASS);
}
#endif

#if CONFIG_TEST_ADC_CH1
ZTEST(adc24_differential, test_adc24_channel_1_diff_input)
{
	zassert_true(test_channels(ADC_CHANNEL_1, ADC_UNMASK_CHANNEL_1) == TC_PASS);
}
#endif

#if CONFIG_TEST_ADC_CH2
ZTEST(adc24_differential, test_adc24_channel_2_diff_input)
{
	zassert_true(test_channels(ADC_CHANNEL_2, ADC_UNMASK_CHANNEL_2) == TC_PASS);
}
#endif

#if CONFIG_TEST_ADC_CH3
ZTEST(adc24_differential, test_adc24_channel_3_diff_input)
{
	zassert_true(test_channels(ADC_CHANNEL_3, ADC_UNMASK_CHANNEL_3) == TC_PASS);
}
#endif
#if !(CONFIG_TEST_ADC_CH0 || CONFIG_TEST_ADC_CH1 || \
	CONFIG_TEST_ADC_CH2 || CONFIG_TEST_ADC_CH3)
ZTEST(adc24_differential, test_adc24_channel_4_diff_input_error_scenario)
{
	zassert_true(test_channels(ADC_CHANNEL_4, ADC_UNMASK_CHANNEL_4) == TC_PASS);
}

ZTEST(adc24_differential, test_adc24_channel_5_diff_input_error_scenario)
{
	zassert_true(test_channels(ADC_CHANNEL_5, ADC_UNMASK_CHANNEL_5) == TC_PASS);
}

ZTEST(adc24_differential, test_adc24_channel_6_diff_input_error_scenario)
{
	zassert_true(test_channels(ADC_CHANNEL_6, ADC_UNMASK_CHANNEL_6) == TC_PASS);
}

ZTEST(adc24_differential, test_adc24_channel_7_diff_input_error_scenario)
{
	zassert_true(test_channels(ADC_CHANNEL_7, ADC_UNMASK_CHANNEL_7) == TC_PASS);
}

#endif /* !CONTINUOUS && !MULTICH */
#endif
#if (CONFIG_TEST_ADC_CONTINUOUS && !CONFIG_TEST_ADC_MULTICH)
ZTEST(adc24_differential, test_adc24_continuousMode)
{
	All_channel = 1;
	zassert_true(test_channels(0, 0) == TC_PASS);
	All_channel = 0;
}
#endif

#if CONFIG_TEST_ADC_MULTICH
ZTEST(adc24_multi_channel, test_adc24_continuousMode_multi_channel)
{
	All_channel = 1;
	zassert_true(test_channels(0, 0) == TC_PASS);
	All_channel = 0;
}
#endif

#endif /* CONFIG_TEST_ADC24 */
```

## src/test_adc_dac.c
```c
/*
 * Copyright (C) 2026 Alif Semiconductor.
 * SPDX-License-Identifier: Apache-2.0
 *
 * DAC0 drives a DC voltage. ADC12 or ADC24 reads it back.
 *
 * Wire DAC0 (pinctrl P2_3) to the ADC pin for the overlay in use:
 * ADC12 instance 1 (Balletto/B1 preferred): P2_3 to ADC1 CH0 P0_6
 *   — alif_adc1_dac0.overlay
 * ADC12 instance 0: P2_3 to ADC0 CH0 P0_0 — alif_adc12_dac0.overlay
 *   (P0_0 is UART0 RX mux; often stuck near Vref on DevKit — avoid on B1)
 * ADC24: P2_3 to P0_0, and tie channel 0 negative P0_1 to GND
 *   — alif_adc24_dac0.overlay
 *
 * DAC12 and ADC12 both use the 1.8 V reference, so a 12-bit DAC code is the
 * expected ADC12 code. ADC24 full scale is that same reference on a 24-bit
 * differential converter, so the expected code is the DAC code shifted left
 * by 11 (2^23 / 2^12).
 */
#include "test_adc.h"

#if CONFIG_TEST_ADC_DAC

#include <zephyr/drivers/dac.h>

LOG_MODULE_DECLARE(ALIF_ADC, LOG_LEVEL_INF);

#define DAC_NODE DT_ALIAS(dac)
#define DAC_CHANNEL_ID 0
#define DAC_RESOLUTION 12

/* Default ADC node: 256 averages, right shift 8. The sample is the code. */
#define ADC12_TOLERANCE 160
/* ADC24: at least 2^16 counts, or 12.5% of the expected code. */
#define ADC24_TOLERANCE_MIN 65536

static const uint16_t dac_steps[] = { 0, 512, 1024, 2048, 3072, 3584 };

static uint32_t adc_buffer;

static const struct dac_channel_cfg dac_ch_cfg = {
	.channel_id = DAC_CHANNEL_ID,
	.resolution = DAC_RESOLUTION,
	.buffered = false,
};

static enum adc_action adc_done(const struct device *dev,
				const struct adc_sequence *sequence,
				uint16_t sampling_index)
{
	ARG_UNUSED(dev);
	ARG_UNUSED(sequence);
	ARG_UNUSED(sampling_index);

	return ADC_ACTION_FINISH;
}

static const struct device *init_dac(void)
{
	int ret;
	const struct device *dac_dev = DEVICE_DT_GET(DAC_NODE);

	zassert_true(device_is_ready(dac_dev), "DAC device is not ready");

	ret = dac_channel_setup(dac_dev, &dac_ch_cfg);
	zassert_equal(ret, 0, "DAC channel setup failed with code %d", ret);

	return dac_dev;
}

static const struct device *init_adc(bool differential)
{
	int ret;
	const struct device *adc_dev = DEVICE_DT_GET(ADC);
	struct adc_channel_cfg channel_cfg = {
		.differential = differential,
		.channel_id = 0,
	};

	zassert_true(device_is_ready(adc_dev), "ADC device is not ready");

	ret = adc_channel_setup(adc_dev, &channel_cfg);
	zassert_equal(ret, 0, "ADC channel setup failed with code %d", ret);

	return adc_dev;
}

static int32_t read_adc(const struct device *adc_dev)
{
	int ret;
	struct adc_sequence_options options = {
		.callback = adc_done,
	};
	struct adc_sequence sequence = {
		.options = &options,
		.buffer = &adc_buffer,
		.buffer_size = sizeof(adc_buffer),
		.channels = BIT(0),
	};

	adc_buffer = 0;
	ret = adc_read(adc_dev, &sequence);
	zassert_equal(ret, 0, "adc_read() failed with code %d", ret);

	return (int32_t)adc_buffer;
}

static void check_dac_steps(const struct device *dac_dev, const struct device *adc_dev,
			    bool adc24)
{
	for (size_t i = 0; i < ARRAY_SIZE(dac_steps); i++) {
		uint16_t dac_code = dac_steps[i];
		int32_t expected;
		int32_t tolerance;
		int32_t code;
		int ret;

		ret = dac_write_value(dac_dev, DAC_CHANNEL_ID, dac_code);
		zassert_equal(ret, 0, "dac_write_value(%u) failed with code %d",
			      dac_code, ret);

		/* DAC output rate is up to 1 kHz. Let the pin settle. */
		k_msleep(20);

		code = read_adc(adc_dev);

		if (adc24) {
			expected = (int32_t)dac_code << 11;
			tolerance = expected / 8;
			if (tolerance < ADC24_TOLERANCE_MIN) {
				tolerance = ADC24_TOLERANCE_MIN;
			}
			LOG_INF("ADC24 code %d for DAC %u (expected %d)",
				code, dac_code, expected);
		} else {
			expected = dac_code;
			tolerance = ADC12_TOLERANCE;
			LOG_INF("ADC12 code %d for DAC %u (expected %d +/- %d)",
				code, dac_code, expected, tolerance);
		}
		zassert_true(code >= expected - tolerance && code <= expected + tolerance,
			     "ADC code %d outside expected %d +/- %d for DAC %u",
			     code, expected, tolerance, dac_code);
	}
}

#if CONFIG_TEST_ADC24
ZTEST(adc24_differential, test_adc24_reads_dac0)
{
	const struct device *dac_dev = init_dac();
	const struct device *adc_dev = init_adc(true);

	LOG_INF("ADC24 differential channel 0 reading DAC0");
	check_dac_steps(dac_dev, adc_dev, true);
}
#else
ZTEST(adc_single_ended, test_adc12_reads_dac0)
{
	const struct device *dac_dev = init_dac();
	const struct device *adc_dev = init_adc(false);

	LOG_INF("ADC12 channel 0 reading DAC0 (wire P2_3 to ADC input)");
	check_dac_steps(dac_dev, adc_dev, false);
}
#endif

#endif /* CONFIG_TEST_ADC_DAC */
```

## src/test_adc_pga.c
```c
/*
 * Copyright (C) 2026 Alif Semiconductor.
 * SPDX-License-Identifier: Apache-2.0
 *
 * PGA gain is programmed by a gain overlay (pga_enable + pga_gain). This
 * testcase reads one channel and logs the configured gain so the suite name
 * is clearly a PGA gain run, not a plain single-ended channel test.
 */
#include "test_adc.h"

#if CONFIG_TEST_ADC_PGA

LOG_MODULE_DECLARE(ALIF_ADC, LOG_LEVEL_INF);

static int pga_channel_id(void)
{
#if !CONFIG_TEST_ADC24 && CONFIG_TEST_ADC_DIFFERENTIAL
	/*
	 * ADC12 differential mode uses logical channel IDs, same pairs as
	 * test_adc12.c: CH0+CH1 -> 0, CH2+CH3 -> 1, CH4+CH5 -> 2.
	 */
#if CONFIG_TEST_ADC_CH4 && CONFIG_TEST_ADC_CH5
	return ADC_CHANNEL_2;
#elif CONFIG_TEST_ADC_CH2 && CONFIG_TEST_ADC_CH3
	return ADC_CHANNEL_1;
#elif CONFIG_TEST_ADC_CH0 && CONFIG_TEST_ADC_CH1
	return ADC_CHANNEL_0;
#endif
#endif
#if CONFIG_TEST_ADC_CH7
	return ADC_CHANNEL_7;
#elif CONFIG_TEST_ADC_CH6
	return ADC_CHANNEL_6;
#elif CONFIG_TEST_ADC_CH5
	return ADC_CHANNEL_5;
#elif CONFIG_TEST_ADC_CH4
	return ADC_CHANNEL_4;
#elif CONFIG_TEST_ADC_CH3
	return ADC_CHANNEL_3;
#elif CONFIG_TEST_ADC_CH2
	return ADC_CHANNEL_2;
#elif CONFIG_TEST_ADC_CH1
	return ADC_CHANNEL_1;
#elif CONFIG_TEST_ADC_CH0
	return ADC_CHANNEL_0;
#else
	return ADC_CHANNEL_1;
#endif
}

static void test_pga_gain(bool differential)
{
	int ret;
	int channel = pga_channel_id();
	uint32_t mask = BIT(channel);
	const struct device *adc_dev = DEVICE_DT_GET(ADC);
	struct adc_channel_cfg channel_cfg = {
		.differential = differential,
		.channel_id = channel,
	};
	struct adc_sequence_options options = {
		.callback = adc_call_back,
		.user_data = &comparator,
	};
	struct adc_sequence sequence = {
		.options = &options,
		.buffer = buffer,
		.buffer_size = sizeof(buffer),
		.channels = mask,
	};

	zassert_true(device_is_ready(adc_dev), "ADC device is not ready");

	LOG_INF("PGA gain test: %s", DT_PROP(ADC, pga_gain));
	LOG_INF("PGA enabled, sampling channel %d", channel);

	ret = adc_channel_setup(adc_dev, &channel_cfg);
	zassert_equal(ret, 0, "ADC channel setup failed with code %d", ret);

	ret = adc_read(adc_dev, &sequence);
	zassert_equal(ret, 0, "adc_read() failed with code %d", ret);
	adc_assert_samples(mask);

	LOG_INF("Channel %d value is %x", channel, buffer[0]);
	LOG_INF("ADC PGA sampling Done");
}

#if CONFIG_TEST_ADC24
#if CONFIG_TEST_ADC_MULTICH
ZTEST(adc24_multi_channel, test_adc24_pga_gain)
#else
ZTEST(adc24_differential, test_adc24_pga_gain)
#endif
{
	test_pga_gain(true);
}
#else
#if CONFIG_TEST_ADC_MULTICH
ZTEST(adc12_multi_channel, test_adc12_pga_gain)
#elif CONFIG_TEST_ADC_DIFFERENTIAL
ZTEST(adc12_differential, test_adc12_pga_gain)
#else
ZTEST(adc_single_ended, test_adc12_pga_gain)
#endif
{
	test_pga_gain(IS_ENABLED(CONFIG_TEST_ADC_DIFFERENTIAL));
}
#endif

#endif /* CONFIG_TEST_ADC_PGA */
```

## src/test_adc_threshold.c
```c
/*
 * Copyright (C) 2026 Alif Semiconductor.
 * SPDX-License-Identifier: Apache-2.0
 *
 * Comparator threshold and window detection. The hardware raises comp_a and
 * comp_b interrupts when the sample crosses threshold A or B. The ztest name
 * matches the overlay mode: above, below, or window — not a plain channel test.
 */
#include "test_adc.h"

#if CONFIG_TEST_ADC_THRESHOLD

LOG_MODULE_DECLARE(ALIF_ADC, LOG_LEVEL_INF);

static int threshold_channel_id(void)
{
#if !CONFIG_TEST_ADC24 && CONFIG_TEST_ADC_DIFFERENTIAL
	/*
	 * ADC12 differential mode uses logical channel IDs, same pairs as
	 * test_adc12.c: CH0+CH1 -> 0, CH2+CH3 -> 1, CH4+CH5 -> 2.
	 */
#if CONFIG_TEST_ADC_CH4 && CONFIG_TEST_ADC_CH5
	return ADC_CHANNEL_2;
#elif CONFIG_TEST_ADC_CH2 && CONFIG_TEST_ADC_CH3
	return ADC_CHANNEL_1;
#elif CONFIG_TEST_ADC_CH0 && CONFIG_TEST_ADC_CH1
	return ADC_CHANNEL_0;
#endif
#endif
#if CONFIG_TEST_ADC_CH7
	return ADC_CHANNEL_7;
#elif CONFIG_TEST_ADC_CH6
	return ADC_CHANNEL_6;
#elif CONFIG_TEST_ADC_CH5
	return ADC_CHANNEL_5;
#elif CONFIG_TEST_ADC_CH4
	return ADC_CHANNEL_4;
#elif CONFIG_TEST_ADC_CH3
	return ADC_CHANNEL_3;
#elif CONFIG_TEST_ADC_CH2
	return ADC_CHANNEL_2;
#elif CONFIG_TEST_ADC_CH1
	return ADC_CHANNEL_1;
#elif CONFIG_TEST_ADC_CH0
	return ADC_CHANNEL_0;
#else
	return ADC_CHANNEL_0;
#endif
}

static enum adc_action threshold_done(const struct device *dev,
				      const struct adc_sequence *sequence,
				      uint16_t sampling_index)
{
	ARG_UNUSED(dev);
	ARG_UNUSED(sequence);
	ARG_UNUSED(sampling_index);

	return ADC_ACTION_FINISH;
}

static void log_comparator_events(uint32_t sample)
{
	LOG_INF("Sample 0x%x, threshold A 0x%x, threshold B 0x%x",
		sample,
		DT_PROP(ADC, comparator_threshold_a),
		DT_PROP(ADC, comparator_threshold_b));

#if DT_ENUM_HAS_VALUE(ADC, comparator_threshold_comparison, ABOVE_THRESHOLD_A_AND_B)
	LOG_INF("Comparator mode: above threshold A and B");
#elif DT_ENUM_HAS_VALUE(ADC, comparator_threshold_comparison, BELOW_THRESHOLD_A_AND_B)
	LOG_INF("Comparator mode: below threshold A and B");
#else
	LOG_INF("Comparator mode: window between or outside A and B");
#endif

	LOG_INF("Comparator interrupt status 0x%x", comparator);
	if (comparator & ADC_COMPARATOR_THRESHOLD_ABOVE_A) {
		LOG_INF("Interrupt: sample above threshold A");
	}
	if (comparator & ADC_COMPARATOR_THRESHOLD_ABOVE_B) {
		LOG_INF("Interrupt: sample above threshold B");
	}
	if (comparator & ADC_COMPARATOR_THRESHOLD_BELOW_A) {
		LOG_INF("Interrupt: sample below threshold A");
	}
	if (comparator & ADC_COMPARATOR_THRESHOLD_BELOW_B) {
		LOG_INF("Interrupt: sample below threshold B");
	}
	if (comparator & ADC_COMPARATOR_THRESHOLD_BETWEEN_A_B) {
		LOG_INF("Interrupt: sample inside window A..B");
	}
	if (comparator & ADC_COMPARATOR_THRESHOLD_OUTSIDE_A_B) {
		LOG_INF("Interrupt: sample outside window A..B");
	}
}

static void test_threshold_interrupt(bool differential)
{
	int ret;
	int channel = threshold_channel_id();
	uint32_t mask = BIT(channel);
	const struct device *adc_dev = DEVICE_DT_GET(ADC);
	struct adc_channel_cfg channel_cfg = {
		.differential = differential,
		.channel_id = channel,
	};
	struct adc_sequence_options options = {
		.callback = threshold_done,
		.user_data = &comparator,
	};
	struct adc_sequence sequence = {
		.options = &options,
		.buffer = buffer,
		.buffer_size = sizeof(buffer),
		.channels = mask,
	};

	zassert_true(device_is_ready(adc_dev), "ADC device is not ready");

#if DT_ENUM_HAS_VALUE(ADC, comparator_threshold_comparison, ABOVE_THRESHOLD_A_AND_B)
	LOG_INF("Threshold above test, sampling channel %d", channel);
#elif DT_ENUM_HAS_VALUE(ADC, comparator_threshold_comparison, BELOW_THRESHOLD_A_AND_B)
	LOG_INF("Threshold below test, sampling channel %d", channel);
#else
	LOG_INF("Threshold window test, sampling channel %d", channel);
#endif

	ret = adc_channel_setup(adc_dev, &channel_cfg);
	zassert_equal(ret, 0, "ADC channel setup failed with code %d", ret);

	comparator = 0;
	buffer[0] = 0;

	ret = adc_read(adc_dev, &sequence);
	zassert_equal(ret, 0, "adc_read() failed with code %d", ret);

	log_comparator_events(buffer[0]);
}

#if CONFIG_TEST_ADC24
#if CONFIG_TEST_ADC_MULTICH
#if DT_ENUM_HAS_VALUE(ADC, comparator_threshold_comparison, ABOVE_THRESHOLD_A_AND_B)
ZTEST(adc24_multi_channel, test_adc24_threshold_above)
#elif DT_ENUM_HAS_VALUE(ADC, comparator_threshold_comparison, BELOW_THRESHOLD_A_AND_B)
ZTEST(adc24_multi_channel, test_adc24_threshold_below)
#else
ZTEST(adc24_multi_channel, test_adc24_threshold_window)
#endif
{
	test_threshold_interrupt(true);
}
#else
#if DT_ENUM_HAS_VALUE(ADC, comparator_threshold_comparison, ABOVE_THRESHOLD_A_AND_B)
ZTEST(adc24_differential, test_adc24_threshold_above)
#elif DT_ENUM_HAS_VALUE(ADC, comparator_threshold_comparison, BELOW_THRESHOLD_A_AND_B)
ZTEST(adc24_differential, test_adc24_threshold_below)
#else
ZTEST(adc24_differential, test_adc24_threshold_window)
#endif
{
	test_threshold_interrupt(true);
}
#endif
#else /* ADC12 */
#if CONFIG_TEST_ADC_MULTICH
#if DT_ENUM_HAS_VALUE(ADC, comparator_threshold_comparison, ABOVE_THRESHOLD_A_AND_B)
ZTEST(adc12_multi_channel, test_adc12_threshold_above)
#elif DT_ENUM_HAS_VALUE(ADC, comparator_threshold_comparison, BELOW_THRESHOLD_A_AND_B)
ZTEST(adc12_multi_channel, test_adc12_threshold_below)
#else
ZTEST(adc12_multi_channel, test_adc12_threshold_window)
#endif
{
	test_threshold_interrupt(false);
}
#elif CONFIG_TEST_ADC_DIFFERENTIAL
#if DT_ENUM_HAS_VALUE(ADC, comparator_threshold_comparison, ABOVE_THRESHOLD_A_AND_B)
ZTEST(adc12_differential, test_adc12_threshold_above)
#elif DT_ENUM_HAS_VALUE(ADC, comparator_threshold_comparison, BELOW_THRESHOLD_A_AND_B)
ZTEST(adc12_differential, test_adc12_threshold_below)
#else
ZTEST(adc12_differential, test_adc12_threshold_window)
#endif
{
	test_threshold_interrupt(true);
}
#else
#if DT_ENUM_HAS_VALUE(ADC, comparator_threshold_comparison, ABOVE_THRESHOLD_A_AND_B)
ZTEST(adc_single_ended, test_adc12_threshold_above)
#elif DT_ENUM_HAS_VALUE(ADC, comparator_threshold_comparison, BELOW_THRESHOLD_A_AND_B)
ZTEST(adc_single_ended, test_adc12_threshold_below)
#else
ZTEST(adc_single_ended, test_adc12_threshold_window)
#endif
{
	test_threshold_interrupt(false);
}
#endif
#endif /* CONFIG_TEST_ADC24 */

#endif /* CONFIG_TEST_ADC_THRESHOLD */
```
